# MM32SPIN05xq register map
File version: 1.01
CPU: CM0 r0p0, little endian, no MPU, no FPU, 2 interrupt priority bits
Registers are 32-bit, read-write, reset 0x0 unless marked. A register's access mark holds for its fields unless they carry their own. Offsets are from the block's base; [hi:lo] are bit positions.

## IWDG — Independent watchdog
Base 0x40003000
0x00 KR wo — Key register
  [15:0] KEY — Key value
0x04 PR — Prescaler register
  [2:0] PR — Prescaler divider
0x08 RLR reset 0xFFF — Reload register
  [11:0] RL — Watchdog counter reload value
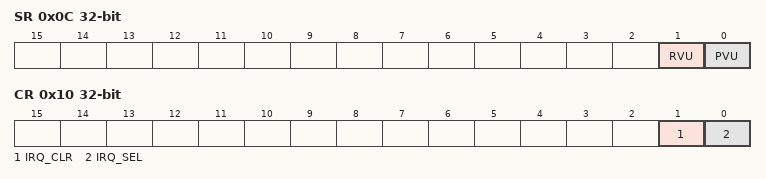
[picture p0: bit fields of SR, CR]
0x0C SR ro — Status register
  [1] RVU — Watchdog counter reload value update
  [0] PVU — Watchdog prescaler value update
0x10 CR — Control register
  [1] IRQ_CLR — Interruput clear
  [0] IRQ_SEL — Interruput select

## PWM — PWM Control
Base 0x40016400
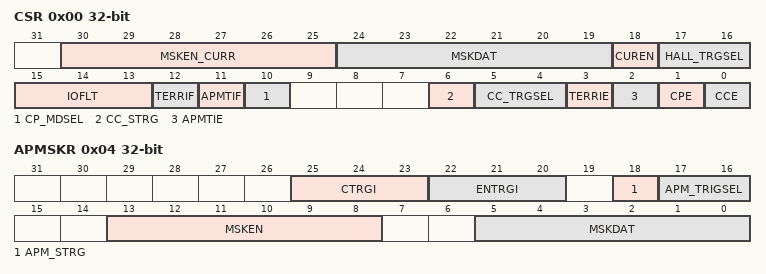
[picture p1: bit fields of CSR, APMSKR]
0x00 CSR — Control PWM output status register
  [30:25] MSKEN_CURR — PWM Output Mask Immediately Enable
  [24:19] MSKDAT — Immediate Output of The Port when PWM is Masked
  [18] CUREN — Enable Current Input Status Value
  [17:16] HALL_TRGSEL — Hall Sensor Trigger 3-channel select
  [15:13] IOFLT — GPIO Input Filter
  [12] TERRIF — Trigger Error Flag
  [11] APMTIF — Auto Phase Mask Trigger Flag
  [10] CP_MDSEL — Current Protection Mode Selection
  [6] CC_STRG — Current Compensation Software Trigger
  [5:4] CC_TRGSEL — Current Protection Trigger Selection
  [3] TERRIE — Trigger Error Interrupt Enable
  [2] APMTIE — Auto Phase Mask Trigger Interrupt Enable
  [1] CPE — Current Protection Enable
  [0] CCE — Current Compensation Enable
0x04 APMSKR — Auto phase mask register
  [25:23] CTRGI — Current Trigger Input
  [22:20] ENTRGI — Expect Next Trigger Input
  [18] APM_STRG — Auto Phase Mask Software Trigger
  [17:16] APM_TRIGSEL — Auto Phase Mask Tigger Selection
  [13:8] MSKEN — PWM Mask Function Enable
  [5:0] MSKDAT — PWM Mask Data
0x08 APMDLR reset 0x1 — Auto phase mask dalay register
  [25:0] APMDLR — *D0

## PWR — Power control
Base 0x40007000
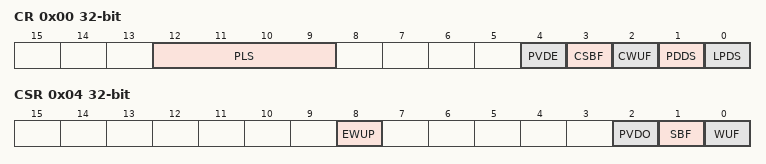
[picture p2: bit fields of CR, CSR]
0x00 CR
  [12:9] PLS — PVD level selection
  [4] PVDE — Power voltage detector enable
  [3] CSBF — Clear standby flag
  [2] CWUF — Clear wakeup flag
  [1] PDDS — Power down deepsleep
  [0] LPDS — Auto Phase Mask delay load register
0x04 CSR
  [8] EWUP — Enable WKUP pin
  [2] PVDO — PVD output
  [1] SBF — Standby flag
  [0] WUF — Wakeup flag

## SPI1 — Serial peripheral interface
Base 0x40013000
Same registers: SPI2 0x40003800
0x00 TXREG
  [31:0] TXREG — Transmit data register
0x04 RXREG ro
  [31:0] RXREG — Receive data register
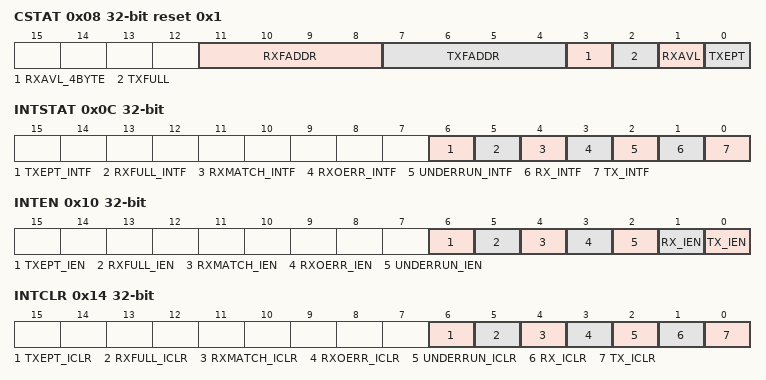
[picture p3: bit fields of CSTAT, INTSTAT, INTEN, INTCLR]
0x08 CSTAT ro reset 0x1
  [11:8] RXFADDR — Transmit FIFO address
  [7:4] TXFADDR — Receive FIFO address
  [3] RXAVL_4BYTE — Receive available 4 byte data message
  [2] TXFULL — Transmitter FIFO full status bit
  [1] RXAVL — Receive available byte data message
  [0] TXEPT — Transmitter empty bit
0x0C INTSTAT
  [6] TXEPT_INTF — Transmitter empty interrupt flag bit
  [5] RXFULL_INTF — RX FIFO full interrupt flag bit
  [4] RXMATCH_INTF — Receive data match the RXDNR number
  [3] RXOERR_INTF — Receive overrun error interrupt flag bit
  [2] UNDERRUN_INTF — SPI underrun interrupt flag bit
  [1] RX_INTF — Receive data available interrupt flag bit
  [0] TX_INTF — Transmit FIFO avialable interrupt flag bit
0x10 INTEN
  [6] TXEPT_IEN — Transmit empty interrupt enable bit
  [5] RXFULL_IEN — Receive FIFO full interrupt enable bit
  [4] RXMATCH_IEN — Receive data complete interrupt enable bit
  [3] RXOERR_IEN — Overrun error interrupt enable bit
  [2] UNDERRUN_IEN — Transmitter underrun interrupt enable bit(SPI slave mode only)
  [1] RX_IEN — Receive FIFO interrupt enable bit
  [0] TX_IEN — Transmit FIFO empty interrupt enable bit
0x14 INTCLR
  [6] TXEPT_ICLR — Transmitter empty interrupt clear bit
  [5] RXFULL_ICLR — Receiver buffer full interrupt clear bit
  [4] RXMATCH_ICLR — Receive completed interrupt clear bit
  [3] RXOERR_ICLR — Overrun error interrupt clear bit
  [2] UNDERRUN_ICLR — Transmitter underrun interrupt clear bit(SPI slave mode only)
  [1] RX_ICLR — Receive interrupt clear bit
  [0] TX_ICLR — Transmitter FIFO empty interrupt clear bit
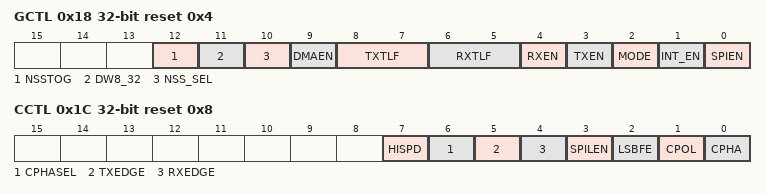
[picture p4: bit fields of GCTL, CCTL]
0x18 GCTL reset 0x4
  [12] NSSTOG — NSS selection signal is automatically flipped
  [11] DW8_32 — Valid byte or double-word data select signal
  [10] NSS_SEL — NSS select signal that from software and hardware
  [9] DMAEN — DMA access mode enable
  [8:7] TXTLF — TX FIFO trigger level bit
  [6:5] RXTLF — RX FIFO trigger level bit
  [4] RXEN — Receive enable bit
  [3] TXEN — Transmit enable bit
  [2] MODE — Master mode bit
  [1] INT_EN — SPI interrupt enable bit
  [0] SPIEN — SPI select bit
0x1C CCTL reset 0x8
  [7] HISPD — High speed slave mode
  [6] CPHASEL — CPHA polarity select
  [5] TXEDGE — Transmit data edge select
  [4] RXEDGE — Receive data edge select
  [3] SPILEN — SPI character length bit
  [2] LSBFE — LSI first enable bit
  [1] CPOL — Clock polarity select bit
  [0] CPHA — Clock phase select bit
0x20 SPBRG reset 0x2
  [15:0] SPBRG — SPI baud rate control register for baud rate
0x24 RXDNR reset 0x1
  [15:0] RXDNR — The register is used to hold a count of to be received bytes in next receive process
0x28 NSSR reset 0xFF
  [0] NSS — Chip select output signal in Master mode
0x2C EXTCTL reset 0x8
  [4:0] EXTLEN — Control SPI data length
